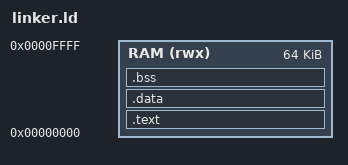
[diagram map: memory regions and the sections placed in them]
/*
 * Linker Script for PicoRV32 Minimal SoC
 * Target: RV32I Bare-Metal
 * Memory: 64 KB Unified Block RAM at 0x00000000
 */

OUTPUT_ARCH("riscv")
ENTRY(_start)

MEMORY
{
    RAM (rwx) : ORIGIN = 0x00000000, LENGTH = 64K
}

SECTIONS
{
    .text :
    {
        . = ALIGN(4);
        *(.text.start)
        *(.text)
        *(.text.*)
        *(.rodata)
        *(.rodata.*)
        *(.srodata)
        *(.srodata.*)
        . = ALIGN(4);
        _etext = .;
    } > RAM

    .data :
    {
        . = ALIGN(4);
        _sdata = .;
        *(.sdata)
        *(.sdata.*)
        *(.data)
        *(.data.*)
        . = ALIGN(4);
        _edata = .;
    } > RAM

    .bss :
    {
        . = ALIGN(4);
        _bss_start = .;
        *(.sbss)
        *(.sbss.*)
        *(.bss)
        *(.bss.*)
        *(COMMON)
        . = ALIGN(4);
        _bss_end = .;
    } > RAM

    . = ALIGN(16);
    _stack_bottom = .;
    _stack_top = ORIGIN(RAM) + LENGTH(RAM);
}
